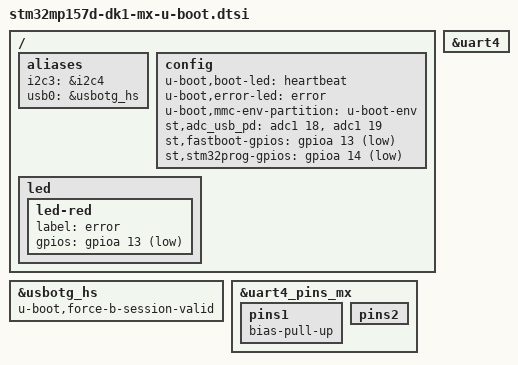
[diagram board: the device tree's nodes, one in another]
// SPDX-License-Identifier: (GPL-2.0-or-later OR BSD-3-Clause)
/*
 * Copyright (C) 2025, STMicroelectronics - All Rights Reserved
 * Author: STM32CubeMX code generation for STMicroelectronics.
 */

/* For more information on Device Tree configuration, please refer to
 * https://wiki.st.com/stm32mpu/wiki/Category:Device_tree_configuration
 */

/* USER CODE BEGIN includes */
#include "stm32mp15-scmi-u-boot.dtsi"
/* USER CODE END includes */

/ {

	/* USER CODE BEGIN root */

	aliases{
		i2c3 = &i2c4;
		usb0 = &usbotg_hs;
	};

	config{
		u-boot,boot-led = "heartbeat";
		u-boot,error-led = "error";
		u-boot,mmc-env-partition = "u-boot-env";
		st,adc_usb_pd = <&adc1 18>, <&adc1 19>;
		st,fastboot-gpios = <&gpioa 13 (GPIO_ACTIVE_LOW | GPIO_PULL_UP)>;
		st,stm32prog-gpios = <&gpioa 14 (GPIO_ACTIVE_LOW | GPIO_PULL_UP)>;
	};

	led{

		led-red{
			label = "error";
			gpios = <&gpioa 13 GPIO_ACTIVE_LOW>;
		};
	};
	/* USER CODE END root */

}; /*root*/

/* USER CODE BEGIN addons */

&uart4 {
	bootph-all;
};

&usbotg_hs {
	u-boot,force-b-session-valid;
};

&uart4_pins_mx {
	bootph-all;
	pins1 {	/* UART4_RX */
		bootph-all;
		/* pull-up on rx to avoid floating level */
		bias-pull-up;
	};
	pins2 {
		bootph-all;
	};
};
/* USER CODE END addons */

